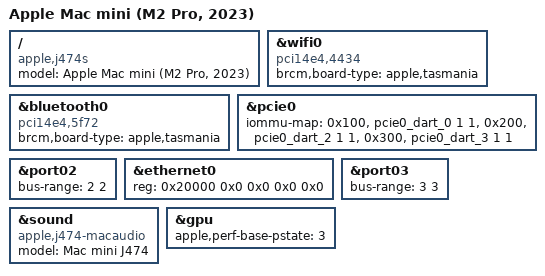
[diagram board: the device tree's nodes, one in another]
// SPDX-License-Identifier: GPL-2.0+ OR MIT
/*
 * Mac mini (M2 Pro, 2023)
 *
 * target-type: J474s
 *
 * Copyright The Asahi Linux Contributors
 */

/dts-v1/;

#include "t6020.dtsi"

/*
 * This model is very similar to M1 and M2 Mac Studio models so base it on those
 * and remove the missing SDHCI controller.
 */

#include "t602x-j474-j475.dtsi"

/ {
	compatible = "apple,j474s", "apple,t6020", "apple,arm-platform";
	model = "Apple Mac mini (M2 Pro, 2023)";
};

/* PCIe devices */
&wifi0 {
	compatible = "pci14e4,4434";
	brcm,board-type = "apple,tasmania";
};

&bluetooth0 {
	compatible = "pci14e4,5f72";
	brcm,board-type = "apple,tasmania";
};

/*
 * port01 is unused, remove the PCIe sdhci0 node from t600x-j375.dtsi and adjust
 * the iommu-map.
 */
/delete-node/ &sdhci0;

&pcie0 {
	iommu-map = <0x100 &pcie0_dart_0 1 1>,
			<0x200 &pcie0_dart_2 1 1>,
			<0x300 &pcie0_dart_3 1 1>;
};

&port02 {
	bus-range = <2 2>;
};

&ethernet0 {
	reg = <0x20000 0x0 0x0 0x0 0x0>;
};

&port03 {
	bus-range = <3 3>;
};

&sound {
	compatible = "apple,j474-macaudio", "apple,j473-macaudio", "apple,macaudio";
	model = "Mac mini J474";
};

&gpu {
	/* Apple does not do this, but they probably should */
	apple,perf-base-pstate = <3>;
};

#include "hwmon-mini.dtsi"
